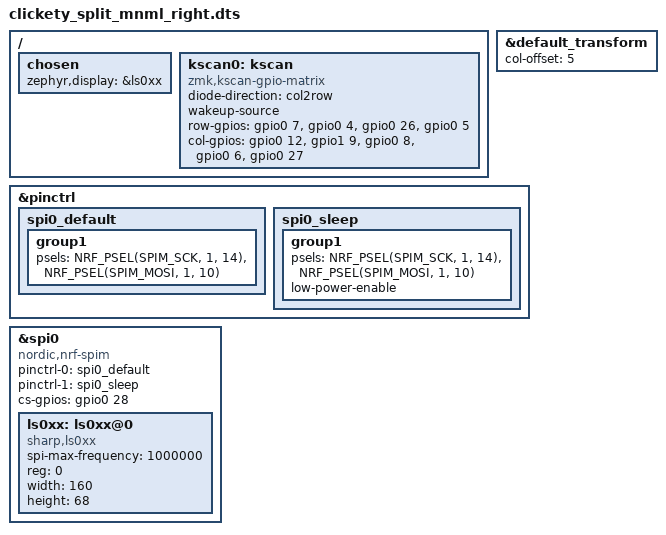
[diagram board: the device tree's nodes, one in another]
/*
 * Copyright (c) 2025 Clickety Split Ltd.
 * SPDX-License-Identifier: MIT
 */

#include "clickety_split_mnml.dtsi"

&default_transform {
    col-offset = <5>;
};

/{
    chosen {
        zephyr,display = &ls0xx;
    };

    kscan0: kscan {
        compatible = "zmk,kscan-gpio-matrix";
        diode-direction = "col2row";
        wakeup-source;

        row-gpios
            = <&gpio0  7 (GPIO_ACTIVE_HIGH | GPIO_PULL_DOWN)>
            , <&gpio0  4 (GPIO_ACTIVE_HIGH | GPIO_PULL_DOWN)>
            , <&gpio0 26 (GPIO_ACTIVE_HIGH | GPIO_PULL_DOWN)>
            , <&gpio0  5 (GPIO_ACTIVE_HIGH | GPIO_PULL_DOWN)>
            ;

        col-gpios
            = <&gpio0 12 GPIO_ACTIVE_HIGH>
            , <&gpio1  9 GPIO_ACTIVE_HIGH>
            , <&gpio0  8 GPIO_ACTIVE_HIGH>
            , <&gpio0  6 GPIO_ACTIVE_HIGH>
            , <&gpio0 27 GPIO_ACTIVE_HIGH>
            ;
    };
};

&pinctrl {
    spi0_default: spi0_default {
        group1 {
            psels = <NRF_PSEL(SPIM_SCK, 1, 14)>,
                <NRF_PSEL(SPIM_MOSI, 1, 10)>;
        };
    };
    spi0_sleep: spi0_sleep {
        group1 {
            psels = <NRF_PSEL(SPIM_SCK, 1, 14)>,
                <NRF_PSEL(SPIM_MOSI, 1, 10)>;
            low-power-enable;
        };
    };
};

&spi0 {
    status = "okay";
    compatible = "nordic,nrf-spim";
    pinctrl-0 = <&spi0_default>;
    pinctrl-1 = <&spi0_sleep>;
    pinctrl-names = "default", "sleep";
    cs-gpios = <&gpio0 28 GPIO_ACTIVE_HIGH>;

    ls0xx: ls0xx@0 {
        compatible = "sharp,ls0xx";
        spi-max-frequency = <1000000>;
        reg = <0>;
        width = <160>;
        height = <68>;
    };
};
